# ATSAM4LC register map
Vendor: Atmel Corporation; Series: SAM4L
CPU: CM4 r0p1, little endian, MPU, no FPU, 4 interrupt priority bits
Registers are 32-bit, write-only, reset 0x0 unless marked. A register's access mark holds for its fields unless they carry their own. Offsets are from the block's base; [hi:lo] are bit positions; 'fields as' and 'values as' point back to an identical list.

## PICOUART
Base 0x400F1400; register names take the prefix PICOUART_
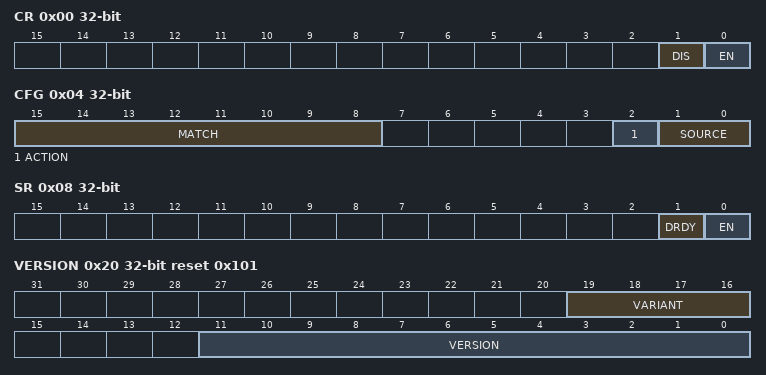
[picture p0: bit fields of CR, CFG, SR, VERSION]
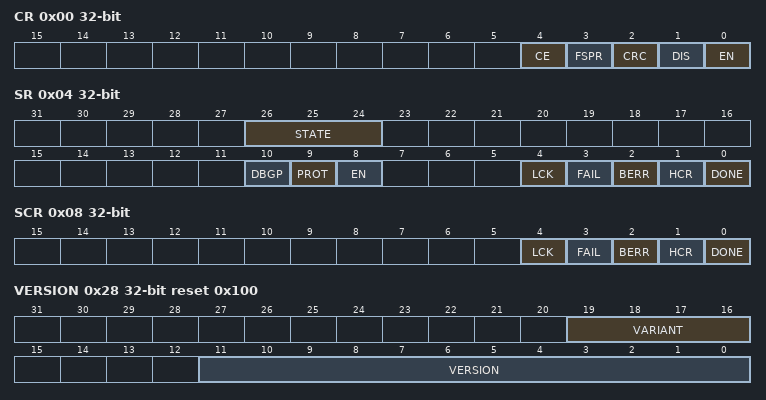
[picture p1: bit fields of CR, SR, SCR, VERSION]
0x00 CR — Control Register
  [1] DIS — Disable
  [0] EN — Enable
0x04 CFG rw — Configuration Register
  [15:8] MATCH — Data Match
  [2] ACTION — Action to perform
  [1:0] SOURCE — Source Enable Mode
0x08 SR ro — Status Register
  [1] DRDY — Data Ready Interrupt Status
  [0] EN — Enable Interrupt Status
0x0C RHR ro — Receive Holding Register
  [31:0] CDATA — Received Data
0x20 VERSION ro reset 0x101
  [19:16] VARIANT — Variant Number
  [11:0] VERSION — Version Number

## SMAP — System Manager Access Port
Base 0x400A3000; register names take the prefix SMAP_
0x00 CR — Control Register
  [4] CE — Chip Erase
  [3] FSPR — Flash Supplementary Page Read
  [2] CRC — User Page Read
  [1] DIS — Disable
  [0] EN — Enable
0x04 SR ro — Status Register
  [26:24] STATE
  [10] DBGP — Debugger Present
  [9] PROT — Protected
  [8] EN — Enabled
  [4] LCK — Lock
  [3] FAIL — Failure
  [2] BERR — Bus error
  [1] HCR — Hold Core reset
  [0] DONE — Operation done
0x08 SCR — Status Clear Register
  [4] LCK — Lock error
  [3] FAIL — Failure
  [2] BERR — Bus error
  [1] HCR — Hold Core Register
  [0] DONE
0x0C ADDR rw — Address Register
  [31:2] ADDR — Address Value
0x10 LENGTH rw
  [31:2] LENGTH
0x14 DATA rw
  [31:0] DATA — Generic data register
0x28 VERSION ro reset 0x100
  [19:16] VARIANT — Variant number
  [11:0] VERSION — Version number
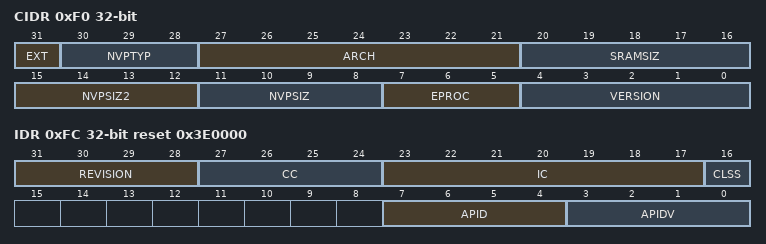
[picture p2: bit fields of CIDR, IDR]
0xF0 CIDR ro — Chip ID Register
  [31] EXT — Extension Flag
  [30:28] NVPTYP — Nonvolatile Program Memory Type
  [27:21] ARCH — Architecture Identifier
  [20:16] SRAMSIZ — Internal SRAM Size
  [15:12] NVPSIZ2 — Second Nonvolatile Program Memory Size
  [11:8] NVPSIZ — Nonvolatile Program Memory Size
  [7:5] EPROC — Embedded Processor
  [4:0] VERSION — Version of the Device
0xF4 EXID ro — Chip ID Extension Register
  [31:0] EXID — Chip ID Extension
0xFC IDR ro reset 0x3E0000 — AP Identification register
  [31:28] REVISION
  [27:24] CC — JEP-106 Continuation Code
  [23:17] IC — JEP-106 Identity Code
  [16] CLSS — Class
  [7:4] APID — AP Identification
  [3:0] APIDV — AP Identification Variant

## TRNG — True Random Number Generator
Base 0x40068000; register names take the prefix TRNG_
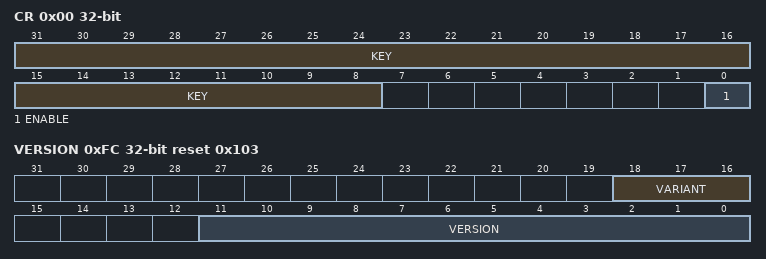
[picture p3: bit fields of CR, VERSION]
0x00 CR — Control Register
  [31:8] KEY — Security Key
  [0] ENABLE — Enables the TRNG to provide random values
0x10 IER — Interrupt Enable Register
  [0] DATRDY — Data Ready Interrupt Enable
0x14 IDR — Interrupt Disable Register
  [0] DATRDY — Data Ready Interrupt Disable
0x18 IMR ro — Interrupt Mask Register
  [0] DATRDY — Data Ready Interrupt Mask
0x1C ISR ro — Interrupt Status Register
  [0] DATRDY — Data Ready Interrupt Status
0x50 ODATA ro — Output Data Register
  [0] ODATA — Output Data
0xFC VERSION ro reset 0x103
  [18:16] VARIANT — Variant Number
  [11:0] VERSION — Version Number

## TWIS0 — Two-wire Slave Interface 0
Base 0x40018400; register names take the prefix TWIS_
Same registers: TWIS1 0x4001C400
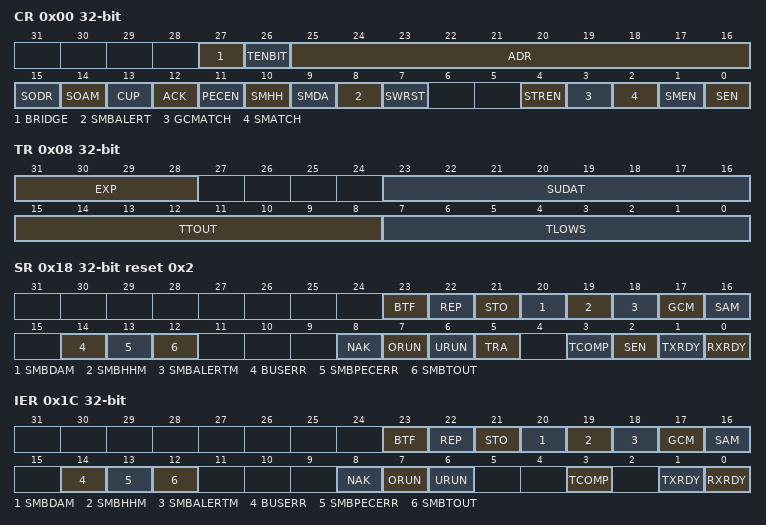
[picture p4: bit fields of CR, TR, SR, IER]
0x00 CR rw — Control Register
  [27] BRIDGE — Bridge Control Enable
  [26] TENBIT — Ten Bit Address Match
  [25:16] ADR — Slave Address
  [15] SODR — Stretch Clock on Data Byte Reception
  [14] SOAM — Stretch Clock on Address Match
  [13] CUP — NBYTES Count Up
  [12] ACK — Slave Receiver Data Phase ACK Value
  [11] PECEN — Packet Error Checking Enable
  [10] SMHH — SMBus Host Header
  [9] SMDA — SMBus Default Address
  [8] SMBALERT — SMBus Alert
  [7] SWRST — Software Reset
  [4] STREN — Clock Stretch Enable
  [3] GCMATCH — General Call Address Match
  [2] SMATCH — Slave Address Match
  [1] SMEN — SMBus Mode Enable
  [0] SEN — Slave Enable
0x04 NBYTES rw
  [7:0] NBYTES — Number of Bytes to Transfer
0x08 TR rw — Timing Register
  [31:28] EXP — Clock Prescaler
  [23:16] SUDAT — Data Setup Cycles
  [15:8] TTOUT — SMBus Ttimeout Cycles
  [7:0] TLOWS — SMBus Tlow:sext Cycles
0x0C RHR ro — Receive Holding Register
  [7:0] RXDATA — Received Data Byte
0x10 THR — Transmit Holding Register
  [7:0] TXDATA — Data Byte to Transmit
0x14 PECR ro — Packet Error Check Register
  [7:0] PEC — Calculated PEC Value
0x18 SR ro reset 0x2 — Status Register
  [23] BTF — Byte Transfer Finished
  [22] REP — Repeated Start Received
  [21] STO — Stop Received
  [20] SMBDAM — SMBus Default Address Match
  [19] SMBHHM — SMBus Host Header Address Match
  [18] SMBALERTM — SMBus Alert Response Address Match
  [17] GCM — General Call Match
  [16] SAM — Slave Address Match
  [14] BUSERR — Bus Error
  [13] SMBPECERR — SMBus PEC Error
  [12] SMBTOUT — SMBus Timeout
  [8] NAK — NAK Received
  [7] ORUN — Overrun
  [6] URUN — Underrun
  [5] TRA — Transmitter Mode
  [3] TCOMP — Transmission Complete
  [2] SEN — Slave Enabled
  [1] TXRDY — TX Buffer Ready
  [0] RXRDY — RX Buffer Ready
0x1C IER — Interrupt Enable Register
  [23] BTF — Byte Transfer Finished
  [22] REP — Repeated Start Received
  [21] STO — Stop Received
  [20] SMBDAM — SMBus Default Address Match
  [19] SMBHHM — SMBus Host Header Address Match
  [18] SMBALERTM — SMBus Alert Response Address Match
  [17] GCM — General Call Match
  [16] SAM — Slave Address Match
  [14] BUSERR — Bus Error
  [13] SMBPECERR — SMBus PEC Error
  [12] SMBTOUT — SMBus Timeout
  [8] NAK — NAK Received
  [7] ORUN — Overrun
  [6] URUN — Underrun
  [3] TCOMP — Transmission Complete
  [1] TXRDY — TX Buffer Ready
  [0] RXRDY — RX Buffer Ready
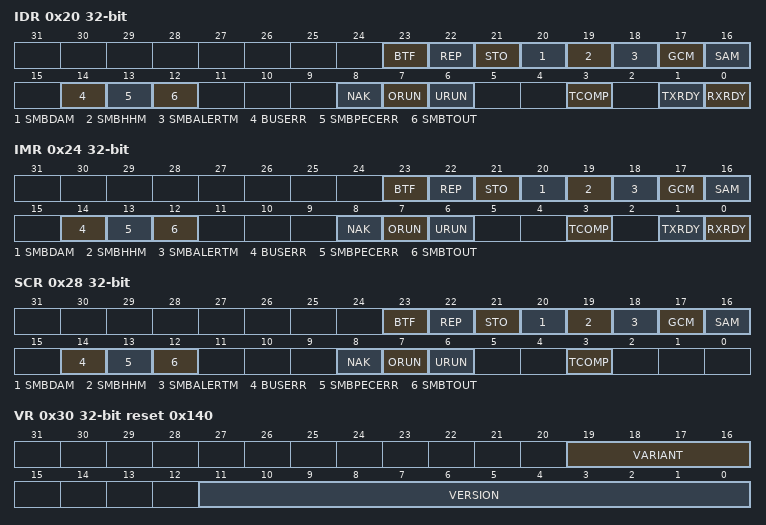
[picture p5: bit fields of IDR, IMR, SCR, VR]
0x20 IDR — Interrupt Disable Register
  fields as IER
0x24 IMR ro — Interrupt Mask Register
  fields as IER
0x28 SCR — Status Clear Register
  [23] BTF — Byte Transfer Finished
  [22] REP — Repeated Start Received
  [21] STO — Stop Received
  [20] SMBDAM — SMBus Default Address Match
  [19] SMBHHM — SMBus Host Header Address Match
  [18] SMBALERTM — SMBus Alert Response Address Match
  [17] GCM — General Call Match
  [16] SAM — Slave Address Match
  [14] BUSERR — Bus Error
  [13] SMBPECERR — SMBus PEC Error
  [12] SMBTOUT — SMBus Timeout
  [8] NAK — NAK Received
  [7] ORUN — Overrun
  [6] URUN — Underrun
  [3] TCOMP — Transmission Complete
0x2C PR ro reset 0x1 — Parameter Register
  [0] HS — HS-mode
0x30 VR ro reset 0x140 — Version Register
  [19:16] VARIANT — Variant Number
  [11:0] VERSION — Version Number
0x34 HSTR rw — HS-mode Timing Register
  [23:16] HDDAT — Data Hold Cycles
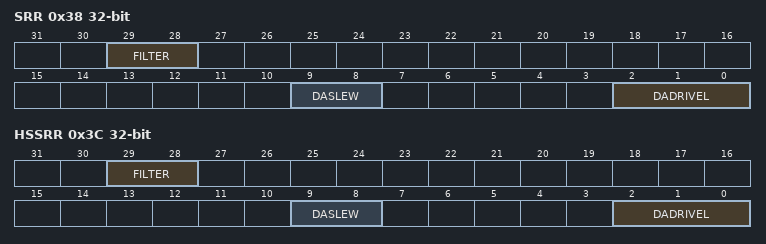
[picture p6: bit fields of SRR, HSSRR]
0x38 SRR rw — Slew Rate Register
  [29:28] FILTER — Input Spike Filter Control
  [9:8] DASLEW — Data Slew Limit
  [2:0] DADRIVEL — Data Drive Strength LOW
0x3C HSSRR rw — HS-mode Slew Rate Register
  fields as SRR

## WDT — Watchdog Timer
Base 0x400F0C00; register names take the prefix WDT_
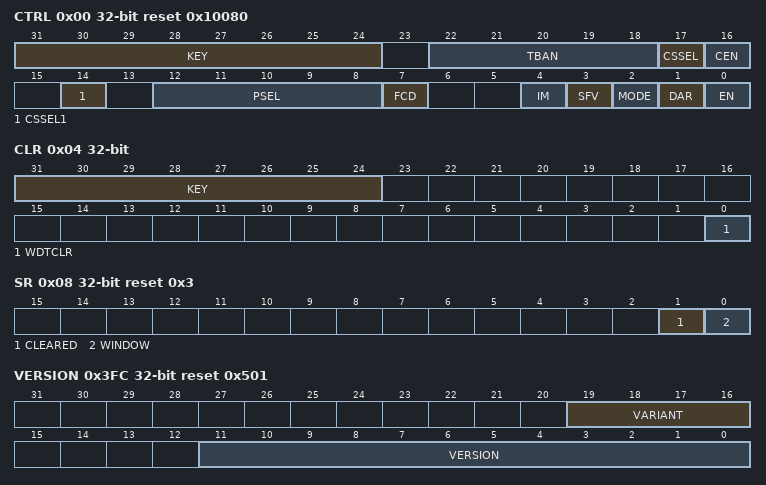
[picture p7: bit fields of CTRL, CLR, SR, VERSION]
0x00 CTRL rw reset 0x10080 — Control Register
  [31:24] KEY
  [22:18] TBAN — TBAN Prescale Select
  [17] CSSEL — Clock Source Selection0
  [16] CEN — Clock Enable
  [14] CSSEL1 — Clock Source Selection1
  [12:8] PSEL — Timeout Prescale Select
  [7] FCD — WDT Fuse Calibration Done
  [4] IM — WDT Interruput Mode
  [3] SFV — WDT Store Final Value
  [2] MODE — WDT Mode
  [1] DAR — WDT Disable After Reset
  [0] EN — WDT Enable
    0=WDT is disabled; 1=WDT is enabled
0x04 CLR — Clear Register
  [31:24] KEY
  [0] WDTCLR — Clear WDT counter
0x08 SR ro reset 0x3 — Status Register
  [1] CLEARED — WDT cleared
  [0] WINDOW — WDT in window
0x0C IER — Interrupt Enable Register
  [2] WINT — Watchdog Interrupt
0x10 IDR — Interrupt Disable Register
  [2] WINT — Watchdog Interrupt
0x14 IMR ro — Interrupt Mask Register
  [2] WINT — Watchdog Interrupt
0x18 ISR ro — Interrupt Status Register
  [2] WINT — Watchdog Interrupt
0x1C ICR — Interrupt Clear Register
  [2] WINT — Watchdog Interrupt
0x3FC VERSION ro reset 0x501
  [19:16] VARIANT — Variant number
  [11:0] VERSION — Version number

## Notices in the file
Atmel Microcontroller Software Support
Copyright (c) 2014, Atmel Corporation
All rights reserved.
Redistribution and use in source and binary forms, with or without
modification, are permitted provided that the following condition is met:
- Redistributions of source code must retain the above copyright notice,
this list of conditions and the disclaimer below.
Atmel's name may not be used to endorse or promote products derived from
this software without specific prior written permission.
DISCLAIMER: THIS SOFTWARE IS PROVIDED BY ATMEL "AS IS" AND ANY EXPRESS OR
IMPLIED WARRANTIES, INCLUDING, BUT NOT LIMITED TO, THE IMPLIED WARRANTIES OF
MERCHANTABILITY, FITNESS FOR A PARTICULAR PURPOSE AND NON-INFRINGEMENT ARE
DISCLAIMED. IN NO EVENT SHALL ATMEL BE LIABLE FOR ANY DIRECT, INDIRECT,
INCIDENTAL, SPECIAL, EXEMPLARY, OR CONSEQUENTIAL DAMAGES (INCLUDING, BUT NOT
LIMITED TO, PROCUREMENT OF SUBSTITUTE GOODS OR SERVICES; LOSS OF USE, DATA,
OR PROFITS; OR BUSINESS INTERRUPTION) HOWEVER CAUSED AND ON ANY THEORY OF
LIABILITY, WHETHER IN CONTRACT, STRICT LIABILITY, OR TORT (INCLUDING
NEGLIGENCE OR OTHERWISE) ARISING IN ANY WAY OUT OF THE USE OF THIS SOFTWARE,
EVEN IF ADVISED OF THE POSSIBILITY OF SUCH DAMAGE.
